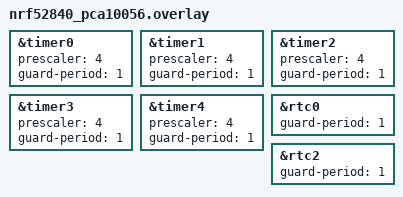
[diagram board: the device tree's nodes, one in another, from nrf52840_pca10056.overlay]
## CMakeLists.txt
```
# SPDX-License-Identifier: Apache-2.0

cmake_minimum_required(VERSION 3.28.0)

find_package(Zephyr REQUIRED HINTS $ENV{ZEPHYR_BASE})
project(counter_basic_api)

FILE(GLOB app_sources src/*.c)
target_sources(app PRIVATE ${app_sources})
```

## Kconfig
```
# Copyright 2025 NXP
# SPDX-License-Identifier: Apache-2.0

config TEST_DRIVER_COUNTER_MCUX_LPC_RTC_HIGHRES
	bool "tests the nxp_lpc_rtc_highres compatible driver"
	default y if COUNTER_MCUX_LPC_RTC_HIGHRES
	help
	  tests the nxp_lpc_rtc_highres compatible driver

config TEST_DRIVER_COUNTER_TOLERANCE
	int "Counter ticks tolerance (%)"
	default 10
	help
	  Error tolerance used in counter driver tests.
	  A number of ticks is estimated and counter is tested against systimer,
	  to verify accuracy. Tolerance is a percentage of deviation allowed for
	  the number of expected ticks.

config TEST_GUARD_PERIOD_US
	int "Guard Period in us"
	default 16000 if COUNTER_MCHP_RTC_G1
	default 200
	help
	  Guard period in us

config TEST_PROCESSING_LIMIT_US
	int "Processing limit in us"
	default 20000 if COUNTER_MCHP_RTC_G1
	default 1000
	help
	  Processing limit in us

config TEST_COUNTER_SHORT_RELATIVE_ALARM_ITERATIONS
	int "Iterations for the short relative alarm test (slow counters)"
	range 1 1000
	default 10
	help
	  Number of set-alarm/wait iterations performed by
	  test_short_relative_alarm for low-frequency (< 1000 Hz) counter
	  instances only; high-frequency counters always use the full 100
	  iterations. Each iteration busy-waits a few counter ticks, so on a
	  slow counter (e.g. a 1 Hz RTC) a large value makes the test run for
	  minutes and risk the test timeout. The default keeps slow-counter
	  coverage while bounding runtime.

source "Kconfig.zephyr"
```

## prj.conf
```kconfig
CONFIG_COUNTER=y
CONFIG_BT=n
CONFIG_ZTEST=y
CONFIG_TEST_USERSPACE=y
CONFIG_LOG=y
```

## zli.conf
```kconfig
CONFIG_ZERO_LATENCY_IRQS=y
```

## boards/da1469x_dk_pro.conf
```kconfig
CONFIG_COUNTER_TIMER1=y
CONFIG_COUNTER_TIMER2=y
CONFIG_COUNTER_TIMER3=y
CONFIG_COUNTER_TIMER4=y
```

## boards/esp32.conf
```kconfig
CONFIG_COUNTER_TMR_ESP32=y
```

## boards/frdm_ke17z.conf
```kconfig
#
# Copyright 2025 NXP
#
# SPDX-License-Identifier: Apache-2.0
#
CONFIG_COUNTER_MCUX_FTM=y
```

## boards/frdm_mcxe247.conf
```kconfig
# SPDX-FileCopyrightText: Copyright 2026 NXP
# SPDX-License-Identifier: Apache-2.0

# LPTMR0 runs from the 1 kHz LPO; the default 200 us guard rounds to 0 ticks.
CONFIG_TEST_GUARD_PERIOD_US=5000
```

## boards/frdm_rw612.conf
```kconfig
#
# Copyright 2025 NXP
#
# SPDX-License-Identifier Apache-2.0
#
CONFIG_PM=y
```

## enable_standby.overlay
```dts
/*
 * Copyright 2025 NXP
 * SPDX-License-Identifier: Apache-2.0
 */

&standby {
	status = "okay";
};
```

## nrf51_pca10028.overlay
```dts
&timer0 {
	prescaler = <4>;
	guard-period = <1>;
};

&timer1 {
	prescaler = <4>;
	guard-period = <1>;
};

&timer2 {
	prescaler = <4>;
	guard-period = <1>;
};

&rtc0 {
	guard-period = <1>;
};
```

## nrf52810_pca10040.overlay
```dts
&timer0 {
	prescaler = <4>;
	guard-period = <1>;
};

&timer1 {
	prescaler = <4>;
	guard-period = <1>;
};

&timer2 {
	prescaler = <4>;
	guard-period = <1>;
};

&rtc0 {
	guard-period = <1>;
};
```

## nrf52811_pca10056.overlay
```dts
&timer0 {
	prescaler = <4>;
	guard-period = <1>;
};

&timer1 {
	prescaler = <4>;
	guard-period = <1>;
};

&timer2 {
	prescaler = <4>;
	guard-period = <1>;
};

&rtc0 {
	guard-period = <1>;
};
```

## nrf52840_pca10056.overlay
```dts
&timer0 {
	prescaler = <4>;
	guard-period = <1>;
};

&timer1 {
	prescaler = <4>;
	guard-period = <1>;
};

&timer2 {
	prescaler = <4>;
	guard-period = <1>;
};

&timer3 {
	prescaler = <4>;
	guard-period = <1>;
};

&timer4 {
	prescaler = <4>;
	guard-period = <1>;
};

&rtc0 {
	guard-period = <1>;
};

&rtc2 {
	guard-period = <1>;
};
```

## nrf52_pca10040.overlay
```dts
&timer0 {
	prescaler = <4>;
	guard-period = <1>;
};

&timer1 {
	prescaler = <4>;
	guard-period = <1>;
};

&timer2 {
	prescaler = <4>;
	guard-period = <1>;
};

&timer3 {
	prescaler = <4>;
	guard-period = <1>;
};

&timer4 {
	prescaler = <4>;
	guard-period = <1>;
};
```

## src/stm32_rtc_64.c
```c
/*
 * SPDX-FileCopyrightText: Copyright The Zephyr Project Contributors
 * SPDX-License-Identifier: Apache-2.0
 */

#include <zephyr/drivers/counter.h>
#include <zephyr/kernel.h>
#include <zephyr/sys/atomic.h>
#include <zephyr/ztest.h>

#if defined(CONFIG_COUNTER_RTC_STM32) && defined(CONFIG_COUNTER_RTC_STM32_SUBSECONDS)

static const struct device *const rtc_dev = DEVICE_DT_GET(DT_INST(0, st_stm32_rtc));
static K_SEM_DEFINE(done, 0, 2);
static atomic_t calls_32;
static atomic_t calls_64;
static bool rearm;
static int rearm_result;
static bool callback_in_isr;
static uint64_t callback_ticks;

static uint32_t alarm_ticks(void)
{
	return MAX(counter_get_frequency(rtc_dev) / 4U, 1U);
}

static void callback_32(const struct device *dev, uint8_t chan, uint32_t ticks, void *user_data)
{
	zassert_equal(dev, rtc_dev);
	zassert_equal(chan, 0);
	zassert_equal(user_data, &done);
	callback_in_isr = k_is_in_isr();
	callback_ticks = ticks;
	atomic_inc(&calls_32);
	k_sem_give(&done);
}

static void callback_64(const struct device *dev, uint8_t chan, uint64_t ticks, void *user_data)
{
	zassert_equal(dev, rtc_dev);
	zassert_equal(chan, 0);
	zassert_equal(user_data, &done);
	callback_in_isr = k_is_in_isr();
	callback_ticks = ticks;
	atomic_inc(&calls_64);
	if (rearm) {
		struct counter_alarm_cfg cfg = {
			.callback = callback_32,
			.ticks = alarm_ticks(),
			.user_data = &done,
		};

		rearm = false;
		rearm_result = counter_set_channel_alarm(dev, 0, &cfg);
	}
	k_sem_give(&done);
}

static void before(void *fixture)
{
	ARG_UNUSED(fixture);
	zassert_true(device_is_ready(rtc_dev));
	zassert_ok(counter_cancel_channel_alarm(rtc_dev, 0));
	zassert_ok(counter_start(rtc_dev));
	k_sem_reset(&done);
	atomic_clear(&calls_32);
	atomic_clear(&calls_64);
	rearm = false;
	rearm_result = -EIO;
	callback_in_isr = false;
}

static void after(void *fixture)
{
	ARG_UNUSED(fixture);
	zassert_ok(counter_cancel_channel_alarm(rtc_dev, 0));
}

ZTEST(stm32_rtc_64, test_callback_width_and_busy)
{
	struct counter_alarm_cfg cfg_32 = {
		.callback = callback_32,
		.ticks = alarm_ticks(),
		.user_data = &done,
	};
	struct counter_alarm_cfg_64 cfg_64 = {
		.callback = callback_64,
		.ticks = alarm_ticks(),
		.user_data = &done,
	};
	uint64_t now;

	zassert_ok(counter_set_channel_alarm(rtc_dev, 0, &cfg_32));
	zassert_equal(counter_set_channel_alarm_64(rtc_dev, 0, &cfg_64), -EBUSY);
	zassert_ok(k_sem_take(&done, K_SECONDS(3)));
	zassert_equal(atomic_get(&calls_32), 1);
	zassert_equal(atomic_get(&calls_64), 0);
	zassert_true(callback_in_isr);

	zassert_ok(counter_set_channel_alarm_64(rtc_dev, 0, &cfg_64));
	zassert_equal(counter_set_channel_alarm(rtc_dev, 0, &cfg_32), -EBUSY);
	zassert_ok(k_sem_take(&done, K_SECONDS(3)));
	zassert_equal(atomic_get(&calls_32), 1);
	zassert_equal(atomic_get(&calls_64), 1);
	zassert_true(callback_in_isr);
	zassert_ok(counter_get_value_64(rtc_dev, &now));
	zassert_true(now >= callback_ticks);
}

ZTEST(stm32_rtc_64, test_cancel_then_change_width)
{
	struct counter_alarm_cfg_64 cfg_64 = {
		.callback = callback_64,
		.ticks = alarm_ticks() * 2U,
		.user_data = &done,
	};
	struct counter_alarm_cfg cfg_32 = {
		.callback = callback_32,
		.ticks = alarm_ticks(),
		.user_data = &done,
	};

	zassert_ok(counter_set_channel_alarm_64(rtc_dev, 0, &cfg_64));
	zassert_ok(counter_cancel_channel_alarm(rtc_dev, 0));
	zassert_ok(counter_set_channel_alarm(rtc_dev, 0, &cfg_32));
	zassert_ok(k_sem_take(&done, K_SECONDS(3)));
	zassert_equal(k_sem_take(&done, K_SECONDS(1)), -EAGAIN);
	zassert_equal(atomic_get(&calls_32), 1);
	zassert_equal(atomic_get(&calls_64), 0);
}

ZTEST(stm32_rtc_64, test_rearm_from_callback)
{
	struct counter_alarm_cfg_64 cfg = {
		.callback = callback_64,
		.ticks = alarm_ticks(),
		.user_data = &done,
	};

	rearm = true;
	zassert_ok(counter_set_channel_alarm_64(rtc_dev, 0, &cfg));
	zassert_ok(k_sem_take(&done, K_SECONDS(3)));
	zassert_ok(rearm_result);
	zassert_ok(k_sem_take(&done, K_SECONDS(3)));
	zassert_equal(atomic_get(&calls_32), 1);
	zassert_equal(atomic_get(&calls_64), 1);
}

ZTEST(stm32_rtc_64, test_range_and_top)
{
	struct counter_alarm_cfg_64 cfg = {
		.callback = callback_64,
		.ticks = (uint64_t)UINT32_MAX + 1U,
		.user_data = &done,
	};
	struct counter_top_cfg_64 top = {
		.ticks = counter_get_top_value_64(rtc_dev),
		.flags = COUNTER_TOP_CFG_DONT_RESET,
	};

	zassert_equal(top.ticks, counter_get_top_value(rtc_dev));
	zassert_equal(counter_set_channel_alarm_64(rtc_dev, 0, &cfg), -EINVAL);
	zassert_ok(counter_set_top_value_64(rtc_dev, &top));
	top.ticks--;
	zassert_equal(counter_set_top_value_64(rtc_dev, &top), -ENOTSUP);
	top.ticks++;
	top.flags = 0;
	zassert_equal(counter_set_top_value_64(rtc_dev, &top), -ENOTSUP);
}

ZTEST_SUITE(stm32_rtc_64, NULL, NULL, before, after, NULL);

#endif
```

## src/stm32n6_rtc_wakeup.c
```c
/*
 * SPDX-FileCopyrightText: Copyright The Zephyr Project Contributors
 * SPDX-License-Identifier: Apache-2.0
 */

#include <zephyr/drivers/counter.h>
#include <zephyr/irq.h>
#include <zephyr/kernel.h>
#include <zephyr/ztest.h>

#if defined(CONFIG_SOC_SERIES_STM32N6X) && defined(CONFIG_COUNTER_RTC_STM32_SUBSECONDS)

static const struct device *const rtc_dev = DEVICE_DT_GET(DT_INST(0, st_stm32_rtc));
static K_SEM_DEFINE(done, 0, 1);
static bool callback_in_isr;

static void callback(const struct device *dev, uint8_t chan, uint64_t ticks, void *user_data)
{
	ARG_UNUSED(ticks);
	zassert_equal(dev, rtc_dev);
	zassert_equal(chan, 0);
	zassert_equal(user_data, &done);
	callback_in_isr = k_is_in_isr();
	k_sem_give(&done);
}

static void before(void *fixture)
{
	ARG_UNUSED(fixture);
	zassert_true(device_is_ready(rtc_dev));
	zassert_ok(counter_cancel_channel_alarm(rtc_dev, 0));
	zassert_ok(counter_start(rtc_dev));
	zassert_ok(counter_set_guard_period_64(rtc_dev, counter_get_frequency(rtc_dev),
					     COUNTER_GUARD_PERIOD_LATE_TO_SET));
	k_sem_reset(&done);
	callback_in_isr = false;
}

static void after(void *fixture)
{
	ARG_UNUSED(fixture);
	zassert_ok(counter_cancel_channel_alarm(rtc_dev, 0));
	zassert_ok(counter_set_guard_period_64(rtc_dev, 0, COUNTER_GUARD_PERIOD_LATE_TO_SET));
}

ZTEST(stm32n6_rtc_wakeup, test_absolute_future)
{
	uint32_t now;
	struct counter_alarm_cfg_64 cfg = {
		.callback = callback,
		.user_data = &done,
		.flags = COUNTER_ALARM_CFG_ABSOLUTE,
	};

	zassert_ok(counter_get_value(rtc_dev, &now));
	cfg.ticks = (uint32_t)(now + counter_get_frequency(rtc_dev) / 4U);
	zassert_ok(counter_set_channel_alarm_64(rtc_dev, 0, &cfg));
	zassert_ok(k_sem_take(&done, K_SECONDS(3)));
	zassert_true(callback_in_isr);
}

ZTEST(stm32n6_rtc_wakeup, test_late_expiry)
{
	uint32_t now;
	struct counter_alarm_cfg_64 cfg = {
		.callback = callback,
		.user_data = &done,
		.flags = COUNTER_ALARM_CFG_ABSOLUTE,
	};

	zassert_ok(counter_get_value(rtc_dev, &now));
	cfg.ticks = (uint32_t)(now - 1U);
	zassert_equal(counter_set_channel_alarm_64(rtc_dev, 0, &cfg), -ETIME);
	zassert_equal(k_sem_take(&done, K_MSEC(20)), -EAGAIN);
	cfg.flags |= COUNTER_ALARM_CFG_EXPIRE_WHEN_LATE;
	zassert_equal(counter_set_channel_alarm_64(rtc_dev, 0, &cfg), -ETIME);
	zassert_ok(k_sem_take(&done, K_SECONDS(1)));
	zassert_true(callback_in_isr);
}

ZTEST(stm32n6_rtc_wakeup, test_cancel_pending_late_expiry)
{
	uint32_t now;
	unsigned int key;
	int alarm_ret;
	int cancel_ret;
	struct counter_alarm_cfg_64 cfg = {
		.callback = callback,
		.user_data = &done,
		.flags = COUNTER_ALARM_CFG_ABSOLUTE | COUNTER_ALARM_CFG_EXPIRE_WHEN_LATE,
	};

	zassert_ok(counter_get_value(rtc_dev, &now));
	cfg.ticks = (uint32_t)(now - 1U);
	key = irq_lock();
	alarm_ret = counter_set_channel_alarm_64(rtc_dev, 0, &cfg);
	cancel_ret = counter_cancel_channel_alarm(rtc_dev, 0);
	irq_unlock(key);
	zassert_equal(alarm_ret, -ETIME);
	zassert_ok(cancel_ret);
	zassert_equal(k_sem_take(&done, K_MSEC(20)), -EAGAIN);
}

ZTEST(stm32n6_rtc_wakeup, test_guard_range)
{
	uint64_t guard = counter_get_guard_period_64(rtc_dev, COUNTER_GUARD_PERIOD_LATE_TO_SET);

	zassert_equal(counter_set_guard_period_64(rtc_dev, (uint64_t)UINT32_MAX + 1U,
						COUNTER_GUARD_PERIOD_LATE_TO_SET), -EINVAL);
	zassert_equal(counter_get_guard_period_64(rtc_dev,
					 COUNTER_GUARD_PERIOD_LATE_TO_SET), guard);
	zassert_equal(counter_get_guard_period(rtc_dev, COUNTER_GUARD_PERIOD_LATE_TO_SET), guard);
}

ZTEST(stm32n6_rtc_wakeup, test_short_relative_alarm)
{
	struct counter_alarm_cfg_64 cfg = {
		.callback = callback,
		.user_data = &done,
		.ticks = 1U,
	};
	uint32_t tick_us = (uint32_t)counter_ticks_to_us(rtc_dev, 1U);

	/* Keep the generic test's three-tick deadline; do not use its capability skip. */
	for (uint32_t i = 0U; i < 100U; i++) {
		zassert_ok(counter_set_channel_alarm_64(rtc_dev, 0, &cfg));
		k_busy_wait(3U * tick_us);
		zassert_ok(k_sem_take(&done, K_NO_WAIT));
		zassert_true(callback_in_isr);
	}
}

ZTEST(stm32n6_rtc_wakeup, test_absolute_target_during_rearm)
{
	struct counter_alarm_cfg_64 cfg = {
		.callback = callback,
		.user_data = &done,
	};
	uint32_t late_count;
	uint32_t now;

	/* Exercise setup crossing separately from an alarm already in the guard zone. */
	zassert_ok(counter_set_guard_period_64(rtc_dev, 0U, COUNTER_GUARD_PERIOD_LATE_TO_SET));
	for (uint32_t expire = 0U; expire < 2U; expire++) {
		late_count = 0U;
		for (uint32_t i = 0U; i < 100U; i++) {
			int ret;

			cfg.flags = 0U;
			cfg.ticks = 40U * counter_get_frequency(rtc_dev);
			zassert_ok(counter_set_channel_alarm_64(rtc_dev, 0, &cfg));
			k_busy_wait(5000U + i);
			zassert_ok(counter_cancel_channel_alarm(rtc_dev, 0));
			zassert_ok(counter_get_value(rtc_dev, &now));
			cfg.ticks = (uint32_t)(now + 1U);
			cfg.flags = COUNTER_ALARM_CFG_ABSOLUTE |
				(expire != 0U ? COUNTER_ALARM_CFG_EXPIRE_WHEN_LATE : 0U);
			ret = counter_set_channel_alarm_64(rtc_dev, 0, &cfg);
			zassert_true(ret == 0 || ret == -ETIME, "Unexpected alarm error: %d", ret);
			if (ret == -ETIME) {
				late_count++;
				if (expire != 0U) {
					zassert_ok(k_sem_take(&done, K_SECONDS(1)));
					zassert_true(callback_in_isr);
				} else {
					zassert_equal(k_sem_take(&done, K_MSEC(20)), -EAGAIN);
				}
			} else {
				zassert_ok(k_sem_take(&done, K_SECONDS(1)));
			}
			zassert_ok(counter_cancel_channel_alarm(rtc_dev, 0));
		}
		zassert_true(late_count > 0U, "No target crossed during rearm; case not exercised");
	}
}

ZTEST_SUITE(stm32n6_rtc_wakeup, NULL, NULL, before, after, NULL);

#endif

#if defined(CONFIG_SOC_SERIES_STM32N6X) && defined(CONFIG_COUNTER_RTC_STM32) && \
	!defined(CONFIG_COUNTER_RTC_STM32_SUBSECONDS)

static const struct device *const rtc_dev = DEVICE_DT_GET(DT_INST(0, st_stm32_rtc));
static K_SEM_DEFINE(done, 0, 1);

static void callback(const struct device *dev, uint8_t chan, uint32_t ticks, void *user_data)
{
	ARG_UNUSED(ticks);
	zassert_equal(dev, rtc_dev);
	zassert_equal(chan, 0);
	zassert_equal(user_data, &done);
	k_sem_give(&done);
}

ZTEST(stm32n6_rtc_wakeup, test_ckspre_cancel_rearm)
{
	struct counter_alarm_cfg cfg = {
		.callback = callback,
		.user_data = &done,
		/* Beyond the DIV16 range: select CKSPRE without subseconds. */
		.ticks = 40U,
	};

	zassert_true(device_is_ready(rtc_dev));
	zassert_ok(counter_start(rtc_dev));
	for (uint32_t i = 0U; i < 32U; i++) {
		zassert_ok(counter_set_channel_alarm(rtc_dev, 0, &cfg));
		/* Allow enable synchronization before cancelling and immediately rearming. */
		k_busy_wait(5000U);
		zassert_ok(counter_cancel_channel_alarm(rtc_dev, 0));
		zassert_equal(k_sem_take(&done, K_NO_WAIT), -EBUSY);
	}
	/* Finish with a short alarm to verify ownership was released. */
	cfg.ticks = 1U;
	zassert_ok(counter_set_channel_alarm(rtc_dev, 0, &cfg));
	zassert_ok(k_sem_take(&done, K_SECONDS(3)));
	zassert_ok(counter_cancel_channel_alarm(rtc_dev, 0));
}

ZTEST_SUITE(stm32n6_rtc_wakeup, NULL, NULL, NULL, NULL, NULL);

#endif
```
